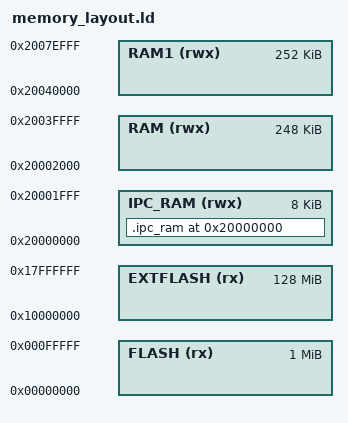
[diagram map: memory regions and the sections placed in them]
/*
 * This file is a part of: https://github.com/brilliantlabsAR/frame-codebase
 *
 * Authored by: Raj Nakarja / Brilliant Labs Ltd. (raj@brilliant.xyz)
 *              Rohit Rathnam / Silicon Witchery AB (rohit@siliconwitchery.com)
 *              Uma S. Gupta / Techno Exponent (umasankar@technoexponent.com)
 *
 * ISC Licence
 *
 * Copyright © 2023 Brilliant Labs Ltd.
 *
 * Permission to use, copy, modify, and/or distribute this software for any
 * purpose with or without fee is hereby granted, provided that the above
 * copyright notice and this permission notice appear in all copies.
 *
 * THE SOFTWARE IS PROVIDED "AS IS" AND THE AUTHOR DISCLAIMS ALL WARRANTIES WITH
 * REGARD TO THIS SOFTWARE INCLUDING ALL IMPLIED WARRANTIES OF MERCHANTABILITY
 * AND FITNESS. IN NO EVENT SHALL THE AUTHOR BE LIABLE FOR ANY SPECIAL, DIRECT,
 * INDIRECT, OR CONSEQUENTIAL DAMAGES OR ANY DAMAGES WHATSOEVER RESULTING FROM
 * LOSS OF USE, DATA OR PROFITS, WHETHER IN AN ACTION OF CONTRACT, NEGLIGENCE OR
 * OTHER TORTIOUS ACTION, ARISING OUT OF OR IN CONNECTION WITH THE USE OR
 * PERFORMANCE OF THIS SOFTWARE.
 */

MEMORY
{
  FLASH (rx) : ORIGIN = 0x00000000, LENGTH = 0x100000
  EXTFLASH (rx) : ORIGIN = 0x10000000, LENGTH = 0x8000000
  IPC_RAM (rwx) : ORIGIN = 0x20000000, LENGTH = 0x2000
  RAM (rwx) : ORIGIN = 0x20002000, LENGTH = 0x3E000
  RAM1 (rwx) : ORIGIN = 0x20040000, LENGTH = 0x3F000
}

SECTIONS
{
  .ipc_ram 0x20000000 (NOLOAD) : {
        KEEP(*(.ipc_ram))
    } > IPC_RAM
}

INCLUDE "nrf_common.ld"
